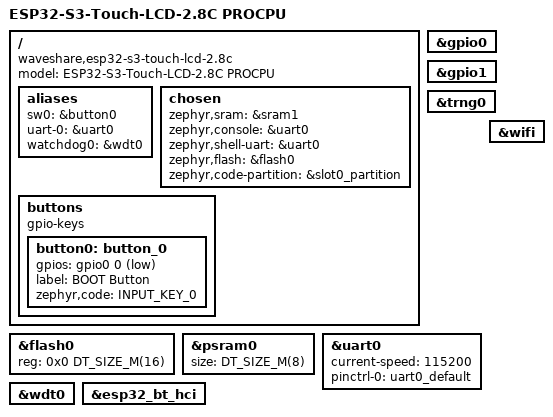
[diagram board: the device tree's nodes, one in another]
/*
 * SPDX-FileCopyrightText: Copyright The Zephyr Project Contributors
 * SPDX-License-Identifier: Apache-2.0
 */

/dts-v1/;

#include <espressif/esp32s3/esp32s3.dtsi>
#include "esp32s3_touch_lcd_2_8c-pinctrl.dtsi"
#include <espressif/partitions_0x0_amp_16M.dtsi>
#include <zephyr/dt-bindings/input/input-event-codes.h>

/ {
	compatible = "waveshare,esp32-s3-touch-lcd-2.8c";
	model = "ESP32-S3-Touch-LCD-2.8C PROCPU";

	aliases {
		sw0 = &button0;
		uart-0 = &uart0;
		watchdog0 = &wdt0;
	};

	chosen {
		zephyr,sram = &sram1;
		zephyr,console = &uart0;
		zephyr,shell-uart = &uart0;
		zephyr,flash = &flash0;
		zephyr,code-partition = &slot0_partition;
	};

	buttons {
		compatible = "gpio-keys";

		button0: button_0 {
			gpios = <&gpio0 0 (GPIO_PULL_UP | GPIO_ACTIVE_LOW)>;
			label = "BOOT Button";
			zephyr,code = <INPUT_KEY_0>;
		};
	};
};

&flash0 {
	reg = <0x0 DT_SIZE_M(16)>;
	ranges = <0x0 0x0 DT_SIZE_M(16)>;
};

&psram0 {
	size = <DT_SIZE_M(8)>;
};

&gpio0 {
	status = "okay";
};

&gpio1 {
	status = "okay";
};

&trng0 {
	status = "okay";
};

&uart0 {
	current-speed = <115200>;
	pinctrl-0 = <&uart0_default>;
	pinctrl-names = "default";
	status = "okay";
};

&wdt0 {
	status = "okay";
};

&esp32_bt_hci {
	status = "okay";
};

&wifi {
	status = "okay";
};
